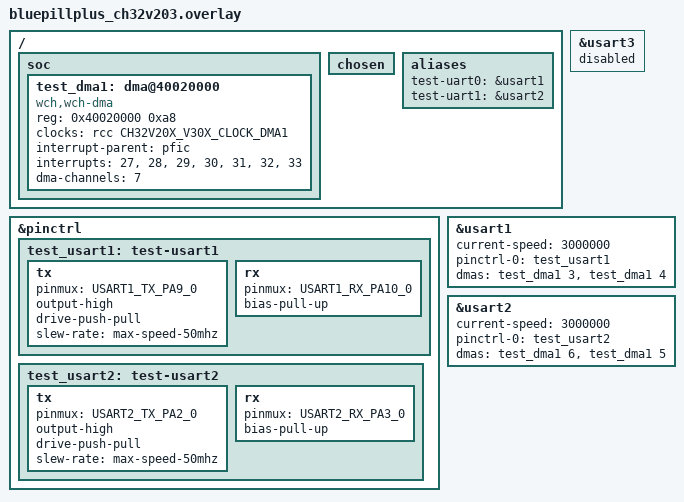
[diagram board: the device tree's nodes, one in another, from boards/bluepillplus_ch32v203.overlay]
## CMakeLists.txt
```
# SPDX-License-Identifier: Apache-2.0

cmake_minimum_required(VERSION 3.20.0)
find_package(Zephyr REQUIRED HINTS $ENV{ZEPHYR_BASE})
project(wch_uart_dma_tests LANGUAGES C)
target_sources(app PRIVATE src/main.c src/api_contract.c)
target_sources_ifdef(CONFIG_WCH_UART_ASYNC_TX app PRIVATE src/tx.c)
target_sources_ifdef(CONFIG_WCH_UART_ASYNC_RX app PRIVATE src/rx.c)
```

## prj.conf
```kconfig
# SPDX-License-Identifier: Apache-2.0

CONFIG_ZTEST=y
CONFIG_WCH_DRIVERS=y
CONFIG_SERIAL=y
CONFIG_UART_WCH_USART=n
CONFIG_WCH_UART=y
CONFIG_UART_INTERRUPT_DRIVEN=y
CONFIG_DMA=y
CONFIG_DMA_WCH=n
CONFIG_WCH_DMA=y
CONFIG_WCH_UART_DMA_PREPARE=y
CONFIG_CONSOLE=n
CONFIG_UART_CONSOLE=n
CONFIG_MAIN_STACK_SIZE=2048
```

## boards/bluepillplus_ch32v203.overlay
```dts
/*
 * DMA1 node adapted from Zephyr ch32v20x_30x_common.dtsi:
 * Copyright (c) 2025 James Bennion-Pedley
 * SPDX-License-Identifier: Apache-2.0
 */

/* Compile fixture for stock Zephyr v4.4.0, not a substitute Gello board. */
#include <zephyr/dt-bindings/pinctrl/ch32v20x_30x-pinctrl.h>
#include <zephyr/dt-bindings/clock/ch32v20x_30x-clocks.h>

/ {
	/* v4.4.0 has the driver but lacks the CH32V203 DMA1 SoC node. */
	soc {
		test_dma1: dma@40020000 {
			compatible = "wch,wch-dma";
			reg = <0x40020000 0xa8>;
			clocks = <&rcc CH32V20X_V30X_CLOCK_DMA1>;
			#dma-cells = <1>;
			interrupt-parent = <&pfic>;
			interrupts = <27>, <28>, <29>, <30>, <31>, <32>, <33>;
			dma-channels = <7>;
			status = "okay";
		};
	};
	chosen {
		/delete-property/ zephyr,console;
		/delete-property/ zephyr,shell-uart;
	};
	aliases {
		test-uart0 = &usart1;
		test-uart1 = &usart2;
	};
};

&pinctrl {
	test_usart1: test-usart1 {
		tx {
			pinmux = <USART1_TX_PA9_0>;
			output-high;
			drive-push-pull;
			slew-rate = "max-speed-50mhz";
		};
		rx {
			pinmux = <USART1_RX_PA10_0>;
			bias-pull-up;
		};
	};
	test_usart2: test-usart2 {
		tx {
			pinmux = <USART2_TX_PA2_0>;
			output-high;
			drive-push-pull;
			slew-rate = "max-speed-50mhz";
		};
		rx {
			pinmux = <USART2_RX_PA3_0>;
			bias-pull-up;
		};
	};
};

&usart3 { status = "disabled"; };

&usart1 {
	status = "okay";
	current-speed = <3000000>;
	pinctrl-0 = <&test_usart1>;
	pinctrl-names = "default";
	dmas = <&test_dma1 3>, <&test_dma1 4>;
	dma-names = "tx", "rx";
};

&usart2 {
	status = "okay";
	current-speed = <3000000>;
	pinctrl-0 = <&test_usart2>;
	pinctrl-names = "default";
	dmas = <&test_dma1 6>, <&test_dma1 5>;
	dma-names = "tx", "rx";
};
```

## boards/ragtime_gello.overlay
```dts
/* SPDX-License-Identifier: Apache-2.0 */

/ {
	aliases {
		test-uart0 = &usart1;
		test-uart1 = &usart2;
	};
};
```

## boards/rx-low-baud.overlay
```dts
/* SPDX-License-Identifier: Apache-2.0 */
/* Append to the board test overlay with EXTRA_DTC_OVERLAY_FILE. */
&usart1 { current-speed = <115200>; };
&usart2 { current-speed = <115200>; };
```

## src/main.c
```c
/* SPDX-License-Identifier: Apache-2.0 */

#include <zephyr/device.h>
#include <zephyr/devicetree.h>
#include <zephyr/drivers/dma.h>
#include <zephyr/drivers/uart.h>
#include <zephyr/ztest.h>

#define UART0_NODE             DT_ALIAS(test_uart0)
#define UART1_NODE             DT_ALIAS(test_uart1)
#define DMA_CTLR(node, dir)    DT_DMAS_CTLR_BY_NAME(node, dir)
#define DMA_CHANNEL(node, dir) DT_DMAS_CELL_BY_NAME(node, dir, channel)

BUILD_ASSERT(IS_ENABLED(CONFIG_WCH_UART), "This test must exercise the external UART driver");
BUILD_ASSERT(IS_ENABLED(CONFIG_WCH_UART_DMA_PREPARE), "DMA preparation must be tested");
BUILD_ASSERT(IS_ENABLED(CONFIG_WCH_DMA), "Use the DMA driver with fixed-channel filtering");
BUILD_ASSERT(!IS_ENABLED(CONFIG_UART_WCH_USART), "Disable the upstream UART driver");
BUILD_ASSERT(DT_NODE_HAS_STATUS(UART0_NODE, okay), "test-uart0 must be enabled");
BUILD_ASSERT(DT_NODE_HAS_STATUS(UART1_NODE, okay), "test-uart1 must be enabled");
BUILD_ASSERT(!DT_SAME_NODE(UART0_NODE, UART1_NODE), "Two distinct UARTs are required");

static const struct device *const uarts[] = {
	DEVICE_DT_GET(UART0_NODE),
	DEVICE_DT_GET(UART1_NODE),
};

static const struct {
	const struct device *controller;
	uint32_t channel;
} dma_requests[] = {
	{DEVICE_DT_GET(DMA_CTLR(UART0_NODE, tx)), DMA_CHANNEL(UART0_NODE, tx)},
	{DEVICE_DT_GET(DMA_CTLR(UART0_NODE, rx)), DMA_CHANNEL(UART0_NODE, rx)},
	{DEVICE_DT_GET(DMA_CTLR(UART1_NODE, tx)), DMA_CHANNEL(UART1_NODE, tx)},
	{DEVICE_DT_GET(DMA_CTLR(UART1_NODE, rx)), DMA_CHANNEL(UART1_NODE, rx)},
};

ZTEST(wch_uart_dma, test_uart_devices_ready)
{
	ARRAY_FOR_EACH(uarts, i) {
		zassert_true(device_is_ready(uarts[i]), "UART %u is not ready", (unsigned)i);
	}
}

ZTEST(wch_uart_dma, test_dma_request_wiring)
{
	ARRAY_FOR_EACH(dma_requests, i) {
		zassert_true(device_is_ready(dma_requests[i].controller), "DMA is not ready");
		for (size_t j = i + 1; j < ARRAY_SIZE(dma_requests); j++) {
			zassert_false(dma_requests[i].controller == dma_requests[j].controller &&
					      dma_requests[i].channel == dma_requests[j].channel,
				      "UART DMA requests must not share a channel");
		}
	}
}

ZTEST(wch_uart_dma, test_async_dma_loopback_pending)
{
	/* Sustained traffic/IDLE qualification remains separate from paced RX. */
	TC_PRINT("SKIP: continuous RX/IDLE qualification requires hardware\n");
	ztest_test_skip();
}

ZTEST(wch_uart_dma, test_fixed_request_allocation)
{
	/* The prepare-only UART driver has not reserved these channels yet. */
	ARRAY_FOR_EACH(dma_requests, i) {
		uint32_t requested = dma_requests[i].channel;
		const struct device *controller = dma_requests[i].controller;
		int channel = dma_request_channel(controller, &requested);

#ifdef CONFIG_WCH_UART_ASYNC_TX
		if (channel >= 0) {
			dma_release_channel(controller, channel);
		}
		zassert_equal(channel, -EINVAL, "Async UART must reserve its fixed DMA channels");
		continue;
#endif
		if (channel != (int)requested) {
			if (channel >= 0) {
				dma_release_channel(controller, channel);
			}
			zassert_unreachable("Fixed channel %u was not allocated", requested);
		}
		int duplicate = dma_request_channel(controller, &requested);

		dma_release_channel(controller, channel);
		if (duplicate >= 0) {
			dma_release_channel(controller, duplicate);
		}
		zassert_equal(duplicate, -EINVAL, "A fixed channel must have one owner");
	}
}

ZTEST_SUITE(wch_uart_dma, NULL, NULL, NULL, NULL, NULL);
```

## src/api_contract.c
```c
/* SPDX-License-Identifier: Apache-2.0 */

#include <zephyr/drivers/uart.h>
#include <zephyr/drivers/dma.h>

/* Compile-only signature checks against each supported Zephyr checkout. */
#define CHECK_API(name, type) _Static_assert(_Generic(&(name), type: 1, default: 0), #name)

typedef int (*callback_api)(const struct device *, uart_callback_t, void *);
typedef int (*tx_api)(const struct device *, const uint8_t *, size_t, int32_t);
typedef int (*rx_api)(const struct device *, uint8_t *, size_t, int32_t);
typedef int (*rx_buffer_api)(const struct device *, uint8_t *, size_t);
typedef int (*device_api)(const struct device *);
typedef int (*dma_status_api)(const struct device *, uint32_t, struct dma_status *);
typedef int (*dma_config_api)(const struct device *, uint32_t, struct dma_config *);

CHECK_API(uart_callback_set, callback_api);
CHECK_API(uart_tx, tx_api);
CHECK_API(uart_tx_abort, device_api);
CHECK_API(uart_rx_enable, rx_api);
CHECK_API(uart_rx_buf_rsp, rx_buffer_api);
CHECK_API(uart_rx_disable, device_api);
CHECK_API(dma_get_status, dma_status_api);
CHECK_API(dma_config, dma_config_api);
```

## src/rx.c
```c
/* SPDX-License-Identifier: Apache-2.0 */
#include <zephyr/drivers/uart.h>
#include <zephyr/ztest.h>

/* Physical local loopbacks required: UART1 TX->RX and UART2 TX->RX.
 * Short, paced packets test ownership/data, NOT lossless streaming or baud.
 */
static const struct device *const ports[] = {
	DEVICE_DT_GET(DT_ALIAS(test_uart0)),
	DEVICE_DT_GET(DT_ALIAS(test_uart1)),
};
static uint8_t payload[2][64];
static uint8_t buffers[2][2][32];
struct rx_result {
	struct k_sem tx_done;
	struct k_sem rx_ready;
	struct k_sem disabled;
	size_t received;
	unsigned int released;
	unsigned int requests;
	int error;
	unsigned int port;
	bool queue_next;
};
static struct rx_result results[2];
/* Debugger-readable milestones: 0 not started, 1 running, 2 passed. Failure
 * also enters ztest_test_fail; a build alone leaves this marker unexecuted.
 */
volatile unsigned int wch_rx_hil_stage;

static void callback(const struct device *dev, struct uart_event *event, void *user)
{
	struct rx_result *result = user;

	switch (event->type) {
	case UART_TX_DONE:
		k_sem_give(&result->tx_done);
		break;
	case UART_TX_ABORTED:
	case UART_RX_STOPPED:
		result->error = -EIO;
		break;
	case UART_RX_BUF_REQUEST:
		if (result->queue_next && result->requests == 0) {
			result->error = uart_rx_buf_rsp(dev, buffers[result->port][1], 32);
		}
		result->requests++;
		break;
	case UART_RX_RDY:
		if (event->data.rx.offset != 0) {
			result->error = -EINVAL;
		}
		result->received += event->data.rx.len;
		k_sem_give(&result->rx_ready);
		break;
	case UART_RX_BUF_RELEASED:
		result->released++;
		break;
	case UART_RX_DISABLED:
		k_sem_give(&result->disabled);
		break;
	default:
		break;
	}
}

static void cleanup(void *fixture)
{
	ARG_UNUSED(fixture);
	ARRAY_FOR_EACH(ports, i) {
		(void)uart_rx_disable(ports[i]);
		(void)uart_tx_abort(ports[i]);
		(void)uart_callback_set(ports[i], NULL, NULL);
	}
}

ZTEST(wch_uart_rx_hardware, test_paced_dual_local_loopback)
{
	wch_rx_hil_stage = 1;
	/* Full 1-byte, full 32-byte, partial 7-byte, then 32+7 handoff/disable. */
	const size_t first_lengths[] = {1, 32, 7, 32};

	ARRAY_FOR_EACH(first_lengths, round) {
		bool chain = round == 3;
		size_t capacity = round == 0 ? 1 : 32;

		ARRAY_FOR_EACH(ports, i) {
			zassert_true(device_is_ready(ports[i]));
			results[i] = (struct rx_result){.port = i, .queue_next = chain};
			k_sem_init(&results[i].tx_done, 0, 1);
			k_sem_init(&results[i].rx_ready, 0, 2);
			k_sem_init(&results[i].disabled, 0, 1);
			memset(buffers[i], 0, sizeof(buffers[i]));
			for (size_t j = 0; j < sizeof(payload[i]); j++) {
				payload[i][j] = (uint8_t)(j ^ (i ? 0xa5 : 0x5a));
			}
			zassert_ok(uart_callback_set(ports[i], callback, &results[i]));
			zassert_ok(
				uart_rx_enable(ports[i], buffers[i][0], capacity, SYS_FOREVER_US));
		}
		ARRAY_FOR_EACH(ports, i) {
			zassert_ok(uart_tx(ports[i], payload[i], first_lengths[round], 100000));
		}
		ARRAY_FOR_EACH(ports, i) {
			zassert_ok(k_sem_take(&results[i].tx_done, K_SECONDS(1)));
			if (chain) {
				zassert_ok(k_sem_take(&results[i].rx_ready, K_SECONDS(1)));
			}
		}
		/* Intentional pacing: even the handoff test makes no gapless claim. */
		k_sleep(K_MSEC(2));
		if (chain) {
			ARRAY_FOR_EACH(ports, i) {
				zassert_ok(uart_tx(ports[i], payload[i] + 32, 7, 100000));
			}
			ARRAY_FOR_EACH(ports, i) {
				zassert_ok(k_sem_take(&results[i].tx_done, K_SECONDS(1)));
			}
			k_sleep(K_MSEC(2));
		}
		ARRAY_FOR_EACH(ports, i) {
			if (chain || round == 2) {
				zassert_ok(uart_rx_disable(ports[i]));
			}
			zassert_ok(k_sem_take(&results[i].disabled, K_SECONDS(1)));
			zassert_ok(results[i].error);
			zassert_equal(results[i].received, first_lengths[round] + (chain ? 7 : 0));
			zassert_equal(results[i].released, chain ? 2 : 1);
			zassert_mem_equal(buffers[i][0], payload[i], first_lengths[round]);
			if (chain) {
				zassert_mem_equal(buffers[i][1], payload[i] + 32, 7);
			}
		}
	}
	wch_rx_hil_stage = 2;
}

ZTEST_SUITE(wch_uart_rx_hardware, NULL, NULL, NULL, cleanup, NULL);
```

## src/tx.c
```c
/* SPDX-License-Identifier: Apache-2.0 */
#include <zephyr/drivers/uart.h>
#include <zephyr/ztest.h>
#include <hal_ch32fun.h>

static const struct device *const ports[] = {
	DEVICE_DT_GET(DT_ALIAS(test_uart0)),
	DEVICE_DT_GET(DT_ALIAS(test_uart1)),
};
static uint8_t payloads[2][128];
struct result {
	struct k_sem done;
	struct uart_event event;
	unsigned int count;
};
static struct result results[2];
volatile struct {
	uint32_t magic, stage;
	struct {
		uint32_t done, aborted, bytes, last_length, last_type, tc_seen, bad_buffer;
	} port[2];
} wch_tx_hil_diag;

static void callback(const struct device *dev, struct uart_event *event, void *user)
{
	struct result *result = user;

	ARG_UNUSED(dev);
	size_t port = result - results;
	wch_tx_hil_diag.port[port].last_type = event->type;
	if (event->type == UART_TX_DONE || event->type == UART_TX_ABORTED) {
		wch_tx_hil_diag.port[port].last_length = event->data.tx.len;
		wch_tx_hil_diag.port[port].bytes += event->data.tx.len;
		wch_tx_hil_diag.port[port].bad_buffer += event->data.tx.buf != payloads[port];
		if (event->type == UART_TX_DONE) {
			wch_tx_hil_diag.port[port].done++;
			wch_tx_hil_diag.port[port].tc_seen +=
				((port ? USART2 : USART1)->STATR & USART_STATR_TC) != 0;
		} else {
			wch_tx_hil_diag.port[port].aborted++;
		}
	}
	result->event = *event;
	result->count++;
	k_sem_give(&result->done);
}

static void cleanup(void *fixture)
{
	ARG_UNUSED(fixture);
	ARRAY_FOR_EACH(ports, i) {
		(void)uart_tx_abort(ports[i]);
		(void)uart_callback_set(ports[i], NULL, NULL);
	}
}

ZTEST(wch_uart_tx_hardware, test_two_port_tx_completion)
{
	wch_tx_hil_diag.magic = 0x57545848;
	wch_tx_hil_diag.stage = 1;
	ARRAY_FOR_EACH(ports, i) {
		zassert_true(device_is_ready(ports[i]));
		k_sem_init(&results[i].done, 0, 1);
		zassert_ok(uart_callback_set(ports[i], callback, &results[i]));
		for (size_t j = 0; j < sizeof(payloads[i]); j++) {
			payloads[i][j] = (uint8_t)(j ^ (i ? 0xa5 : 0x5a));
		}
	}
	const size_t lengths[] = {1, 128};

	ARRAY_FOR_EACH(lengths, n) {
		ARRAY_FOR_EACH(ports, i) {
			results[i].count = 0;
			k_sem_reset(&results[i].done);
			zassert_ok(uart_tx(ports[i], payloads[i], lengths[n], 100000));
		}
		ARRAY_FOR_EACH(ports, i) {
			zassert_ok(k_sem_take(&results[i].done, K_SECONDS(1)), "Missing TX event");
			zassert_equal(results[i].count, 1);
			zassert_equal(results[i].event.type, UART_TX_DONE);
			zassert_equal(results[i].event.data.tx.len, lengths[n]);
			zassert_equal_ptr(results[i].event.data.tx.buf, payloads[i]);
			zassert_equal(uart_tx_abort(ports[i]), -EFAULT);
		}
	}
	ARRAY_FOR_EACH(ports, i) {
		zassert_equal(wch_tx_hil_diag.port[i].tc_seen, ARRAY_SIZE(lengths));
	}
	wch_tx_hil_diag.stage = 2;
}

/* No RX loopback is claimed. Capture PA9/PA2 externally to verify bytes/baud. */
ZTEST_SUITE(wch_uart_tx_hardware, NULL, NULL, NULL, cleanup, NULL);
```
